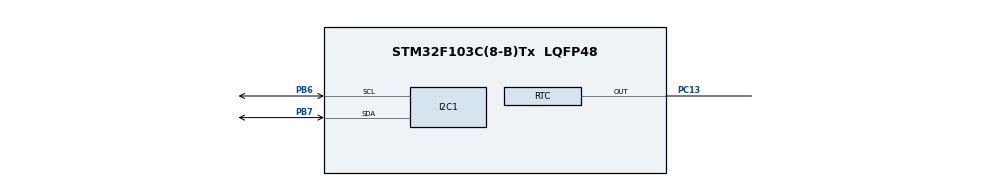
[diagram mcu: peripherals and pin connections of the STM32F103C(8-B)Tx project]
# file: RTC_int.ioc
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I2C1.I2C_Mode=I2C_Fast
Mcu.Family=STM32F1
Mcu.Name=STM32F103C(8-B)Tx
Mcu.Package=LQFP48
NVIC.PriorityGroup=NVIC_PRIORITYGROUP_4
NVIC.RTC_Alarm_IRQn=true\:0\:0\:false\:false\:true\:true\:true\:true
NVIC.RTC_IRQn=true\:0\:0\:false\:false\:true\:true\:true\:true
PA13.Mode=JTAG_4_pins
PA13.Signal=SYS_JTMS-SWDIO
PA14.Mode=JTAG_4_pins
PA14.Signal=SYS_JTCK-SWCLK
PA15.Mode=JTAG_4_pins
PA15.Signal=SYS_JTDI
PB3.Mode=JTAG_4_pins
PB3.Signal=SYS_JTDO-TRACESWO
PB6.Mode=I2C
PB6.Signal=I2C1_SCL
PB7.Mode=I2C
PB7.Signal=I2C1_SDA
PC13-TAMPER-RTC.Mode=RTC OUT
PC13-TAMPER-RTC.Signal=RTC_OUT
ProjectManager.HeapSize=0x200
ProjectManager.StackSize=0x400
ProjectManager.TargetToolchain=STM32CubeIDE
RCC.APB1Freq_Value=8000000
RCC.APB2Freq_Value=8000000
RTC.Minutes_A-RTC\ OUT=1
VP_RTC_VS_RTC_Activate.Mode=RTC_Enabled
VP_RTC_VS_RTC_Calendar.Mode=RTC_Calendar
board=custom

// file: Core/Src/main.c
/* USER CODE BEGIN Header */
/**
  ******************************************************************************
  * @file           : main.c
  * @brief          : Main program body
  ******************************************************************************
  * @attention
  *
  * Copyright (c) 2022 STMicroelectronics.
  * All rights reserved.
  *
  * This software is licensed under terms that can be found in the LICENSE file
  * in the root directory of this software component.
  * If no LICENSE file comes with this software, it is provided AS-IS.
  *
  ******************************************************************************
  */
/* USER CODE END Header */
#include "main.h"

/* USER CODE BEGIN Includes */
#include "fonts.h"
#include "ssd1306.h"
/* USER CODE END Includes */

 I2C_HandleTypeDef hi2c1;

RTC_HandleTypeDef hrtc;

void SystemClock_Config(void);
static void MX_GPIO_Init(void);
static void MX_I2C1_Init(void);
static void MX_RTC_Init(void);
/* USER CODE BEGIN PFP */
RTC_AlarmTypeDef sAlarm;
/* USER CODE END PFP */

/* USER CODE BEGIN 0 */
void HAL_RTC_AlarmAEventCallback(RTC_HandleTypeDef *hrtc)
{
	HAL_ResumeTick();
}
/* USER CODE END 0 */

int main(void)
{

  /* MCU Configuration--------------------------------------------------------*/

  /* Reset of all peripherals, Initializes the Flash interface and the Systick. */
  HAL_Init();

  /* USER CODE BEGIN Init */
  RTC_TimeTypeDef time = {0};
  RTC_DateTypeDef date = {0};
  RTC_AlarmTypeDef sAlarm = {0};
  /* USER CODE END Init */

  /* Configure the system clock */
  SystemClock_Config();

  /* Initialize all configured peripherals */
  MX_GPIO_Init();
  MX_I2C1_Init();
  MX_RTC_Init();

  /* Infinite loop */
  /* USER CODE BEGIN WHILE */
  while (1)
  {
	  SSD1306_GotoXY (0,0);
	  SSD1306_Puts ("HELLO", &Font_16x26, 1);
	  SSD1306_UpdateScreen(); //display
	  HAL_Delay (2000);

	  SSD1306_GotoXY (0,0);
	  SSD1306_Puts ("SLEEP", &Font_16x26, 1);
	  SSD1306_UpdateScreen(); //display
	  HAL_Delay (2000);

	  SSD1306_Clear();

	  HAL_SuspendTick();
	  HAL_PWR_EnterSTOPMode(PWR_LOWPOWERREGULATOR_ON, PWR_STOPENTRY_WFI);

    /* USER CODE END WHILE */
	  HAL_RTC_GetTime(&hrtc, &time, RTC_FORMAT_BIN);
	  HAL_RTC_GetDate(&hrtc, &date, RTC_FORMAT_BIN);
	  time.Minutes += 1;

	  if(time.Minutes >= 60)
	  {
	  time.Hours++;
	  time.Minutes = time.Minutes - 60;
	  }
	  if(time.Hours > 23)
	  {
	  time.Hours = 0;
	  }
	  sAlarm.Alarm = RTC_ALARM_A;
	  sAlarm.AlarmTime.Hours = time.Hours;
	  sAlarm.AlarmTime.Minutes = time.Minutes;
	  sAlarm.AlarmTime.Seconds = time.Seconds;
	  HAL_RTC_SetAlarm_IT(&hrtc, &sAlarm, RTC_FORMAT_BIN);
  }
}

void SystemClock_Config(void)
{
  RCC_OscInitTypeDef RCC_OscInitStruct = {0};
  RCC_ClkInitTypeDef RCC_ClkInitStruct = {0};
  RCC_PeriphCLKInitTypeDef PeriphClkInit = {0};

  /** Initializes the RCC Oscillators according to the specified parameters
  * in the RCC_OscInitTypeDef structure.
  */
  RCC_OscInitStruct.OscillatorType = RCC_OSCILLATORTYPE_HSI|RCC_OSCILLATORTYPE_LSI;
  RCC_OscInitStruct.HSIState = RCC_HSI_ON;
  RCC_OscInitStruct.HSICalibrationValue = RCC_HSICALIBRATION_DEFAULT;
  RCC_OscInitStruct.LSIState = RCC_LSI_ON;
  RCC_OscInitStruct.PLL.PLLState = RCC_PLL_NONE;
  if (HAL_RCC_OscConfig(&RCC_OscInitStruct) != HAL_OK)
  {
    Error_Handler();
  }

  /** Initializes the CPU, AHB and APB buses clocks
  */
  RCC_ClkInitStruct.ClockType = RCC_CLOCKTYPE_HCLK|RCC_CLOCKTYPE_SYSCLK
                              |RCC_CLOCKTYPE_PCLK1|RCC_CLOCKTYPE_PCLK2;
  RCC_ClkInitStruct.SYSCLKSource = RCC_SYSCLKSOURCE_HSI;
  RCC_ClkInitStruct.AHBCLKDivider = RCC_SYSCLK_DIV1;
  RCC_ClkInitStruct.APB1CLKDivider = RCC_HCLK_DIV1;
  RCC_ClkInitStruct.APB2CLKDivider = RCC_HCLK_DIV1;

  if (HAL_RCC_ClockConfig(&RCC_ClkInitStruct, FLASH_LATENCY_0) != HAL_OK)
  {
    Error_Handler();
  }
  PeriphClkInit.PeriphClockSelection = RCC_PERIPHCLK_RTC;
  PeriphClkInit.RTCClockSelection = RCC_RTCCLKSOURCE_LSI;
  if (HAL_RCCEx_PeriphCLKConfig(&PeriphClkInit) != HAL_OK)
  {
    Error_Handler();
  }
}

static void MX_I2C1_Init(void)
{

  hi2c1.Instance = I2C1;
  hi2c1.Init.ClockSpeed = 400000;
  hi2c1.Init.DutyCycle = I2C_DUTYCYCLE_2;
  hi2c1.Init.OwnAddress1 = 0;
  hi2c1.Init.AddressingMode = I2C_ADDRESSINGMODE_7BIT;
  hi2c1.Init.DualAddressMode = I2C_DUALADDRESS_DISABLE;
  hi2c1.Init.OwnAddress2 = 0;
  hi2c1.Init.GeneralCallMode = I2C_GENERALCALL_DISABLE;
  hi2c1.Init.NoStretchMode = I2C_NOSTRETCH_DISABLE;
  if (HAL_I2C_Init(&hi2c1) != HAL_OK)
  {
    Error_Handler();
  }

}

static void MX_RTC_Init(void)
{

  RTC_TimeTypeDef sTime = {0};
  RTC_DateTypeDef DateToUpdate = {0};
  RTC_AlarmTypeDef sAlarm = {0};

  /** Initialize RTC Only
  */
  hrtc.Instance = RTC;
  hrtc.Init.AsynchPrediv = RTC_AUTO_1_SECOND;
  hrtc.Init.OutPut = RTC_OUTPUTSOURCE_ALARM;
  if (HAL_RTC_Init(&hrtc) != HAL_OK)
  {
    Error_Handler();
  }

  /** Initialize RTC and set the Time and Date
  */
  sTime.Hours = 0x0;
  sTime.Minutes = 0x0;
  sTime.Seconds = 0x0;

  if (HAL_RTC_SetTime(&hrtc, &sTime, RTC_FORMAT_BCD) != HAL_OK)
  {
    Error_Handler();
  }
  DateToUpdate.WeekDay = RTC_WEEKDAY_MONDAY;
  DateToUpdate.Month = RTC_MONTH_JANUARY;
  DateToUpdate.Date = 0x1;
  DateToUpdate.Year = 0x0;

  if (HAL_RTC_SetDate(&hrtc, &DateToUpdate, RTC_FORMAT_BCD) != HAL_OK)
  {
    Error_Handler();
  }

  /** Enable the Alarm A
  */
  sAlarm.AlarmTime.Hours = 0x0;
  sAlarm.AlarmTime.Minutes = 0x1;
  sAlarm.AlarmTime.Seconds = 0x0;
  sAlarm.Alarm = RTC_ALARM_A;
  if (HAL_RTC_SetAlarm_IT(&hrtc, &sAlarm, RTC_FORMAT_BCD) != HAL_OK)
  {
    Error_Handler();
  }

}

static void MX_GPIO_Init(void)
{

  /* GPIO Ports Clock Enable */
  __HAL_RCC_GPIOC_CLK_ENABLE();
  __HAL_RCC_GPIOA_CLK_ENABLE();
  __HAL_RCC_GPIOB_CLK_ENABLE();

}

void Error_Handler(void)
{
  __disable_irq();
  while (1)
  {
  }
}
